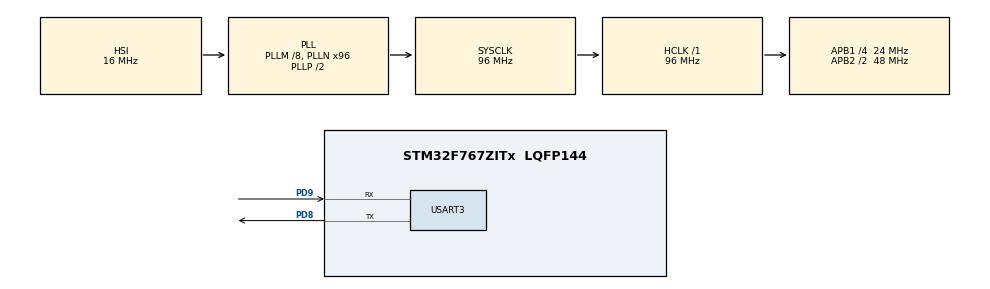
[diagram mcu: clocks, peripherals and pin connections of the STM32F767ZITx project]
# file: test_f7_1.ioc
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CORTEX_M7.CPU_DCache=Enabled
CORTEX_M7.CPU_ICache=Enabled
Mcu.Family=STM32F7
Mcu.Name=STM32F767ZITx
Mcu.Package=LQFP144
NVIC.PriorityGroup=NVIC_PRIORITYGROUP_4
PD8.Mode=Asynchronous
PD8.Signal=USART3_TX
PD9.Mode=Asynchronous
PD9.Signal=USART3_RX
PH0/OSC_IN.Mode=HSE-External-Clock-Source
PH0/OSC_IN.Signal=RCC_OSC_IN
PH1/OSC_OUT.Mode=HSE-External-Clock-Source
PH1/OSC_OUT.Signal=RCC_OSC_OUT
ProjectManager.HeapSize=0x800
ProjectManager.StackSize=0x800
ProjectManager.TargetToolchain=STM32CubeIDE
RCC.AHBFreq_Value=96000000
RCC.APB1CLKDivider=RCC_HCLK_DIV4
RCC.APB1Freq_Value=24000000
RCC.APB1TimFreq_Value=48000000
RCC.APB2CLKDivider=RCC_HCLK_DIV2
RCC.APB2Freq_Value=48000000
RCC.APB2TimFreq_Value=96000000
RCC.CortexFreq_Value=96000000
RCC.HCLKFreq_Value=96000000
RCC.HSE_VALUE=8000000
RCC.HSI_VALUE=16000000
RCC.LSE_VALUE=32768
RCC.PLLM=8
RCC.PLLMUL=RCC_PLL_MUL9
RCC.PLLN=96
RCC.PLLP=2
RCC.PLLQ=9
RCC.PRESCALERUSB=RCC_USBCLKSOURCE_PLL_DIV1_5
RCC.SYSCLKFreq_VALUE=96000000
RCC.SYSCLKSource=RCC_SYSCLKSOURCE_PLLCLK
RCC.SYSCLKSourceVirtual=RCC_SYSCLKSOURCE_PLLCLK
RCC.USBFreq_Value=21333333.333333332
RCC.VCOOutputFreq_Value=192000000
STMicroelectronics.X-CUBE-AI.7.2.0.ActivationBufferSizeList=128
STMicroelectronics.X-CUBE-AI.7.2.0.ActivationBuffers=pool0
STMicroelectronics.X-CUBE-AI.7.2.0.ActivationNames=pool0
STMicroelectronics.X-CUBE-AI.7.2.0.ActivationSizes=AI_SINE_MODEL_DATA_ACTIVATION_1_SIZE
STMicroelectronics.X-CUBE-AI.7.2.0.HeapSize=0x800
STMicroelectronics.X-CUBE-AI.7.2.0.InternalRamActivationBufferMaxSize=AI_SINE_MODEL_DATA_ACTIVATIONS_SIZE
STMicroelectronics.X-CUBE-AI.7.2.0.LatestDirectoryUsed-2042de53a2b5c42e7742469bd244823b2a5d994d889c02ff18ed5b614911f356=C\:\\Users\\iresh\\OneDrive\\Desktop\\Edge AI\\impl
STMicroelectronics.X-CUBE-AI.7.2.0.MaximumNumberOfInputLayer=1
STMicroelectronics.X-CUBE-AI.7.2.0.MaximumNumberOfOutputLayer=1
STMicroelectronics.X-CUBE-AI.7.2.0.MaximumSizeOfInputLayer=1
STMicroelectronics.X-CUBE-AI.7.2.0.MaximumSizeOfOutputLayer=1
STMicroelectronics.X-CUBE-AI.7.2.0.ModelActualCompression-2042de53a2b5c42e7742469bd244823b2a5d994d889c02ff18ed5b614911f356=0.0
STMicroelectronics.X-CUBE-AI.7.2.0.ModelCompression-2042de53a2b5c42e7742469bd244823b2a5d994d889c02ff18ed5b614911f356=Low
STMicroelectronics.X-CUBE-AI.7.2.0.ModelFlashOccupation-2042de53a2b5c42e7742469bd244823b2a5d994d889c02ff18ed5b614911f356=1284
STMicroelectronics.X-CUBE-AI.7.2.0.ModelHashList=2042de53a2b5c42e7742469bd244823b2a5d994d889c02ff18ed5b614911f356
STMicroelectronics.X-CUBE-AI.7.2.0.ModelKind-2042de53a2b5c42e7742469bd244823b2a5d994d889c02ff18ed5b614911f356=TFLITE
STMicroelectronics.X-CUBE-AI.7.2.0.ModelMacc-2042de53a2b5c42e7742469bd244823b2a5d994d889c02ff18ed5b614911f356=353
STMicroelectronics.X-CUBE-AI.7.2.0.ModelName-2042de53a2b5c42e7742469bd244823b2a5d994d889c02ff18ed5b614911f356=sine_model
STMicroelectronics.X-CUBE-AI.7.2.0.ModelNameList=sine_model
STMicroelectronics.X-CUBE-AI.7.2.0.ModelRamOccupation-2042de53a2b5c42e7742469bd244823b2a5d994d889c02ff18ed5b614911f356=128
STMicroelectronics.X-CUBE-AI.7.2.0.ModelStructureFile-2042de53a2b5c42e7742469bd244823b2a5d994d889c02ff18ed5b614911f356=C\:\\Users\\iresh\\OneDrive\\Desktop\\Edge AI\\impl\\sine_model.tflite
STMicroelectronics.X-CUBE-AI.7.2.0.ModelType-2042de53a2b5c42e7742469bd244823b2a5d994d889c02ff18ed5b614911f356=STM32Cube.AI runtime
STMicroelectronics.X-CUBE-AI.7.2.0.ReadyForCodeGeneration=true
STMicroelectronics.X-CUBE-AI.7.2.0.StackSize=0x800
STMicroelectronics.X-CUBE-AI.7.2.0.WorkingBufferStartAddrList=0xFFFFFFFF
STMicroelectronics.X-CUBE-AI.7.2.0.XAaCUBEAaAICcArtificialOoIntelligenceJjCore=true
USART3.VirtualMode-Asynchronous=VM_ASYNC
VP_CRC_VS_CRC.Mode=CRC_Activate
VP_STMicroelectronics.X-CUBE-AI_VS_ArtificialOoIntelligenceJjXAaCUBEAaAI_7.2.0.Mode=ArtificialOoIntelligenceJjXAaCUBEAaAI
board=custom

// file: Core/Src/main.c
/* USER CODE BEGIN Header */
/**
  ******************************************************************************
  * @file           : main.c
  * @brief          : Main program body
  ******************************************************************************
  * @attention
  *
  * Copyright (c) 2022 STMicroelectronics.
  * All rights reserved.
  *
  * This software is licensed under terms that can be found in the LICENSE file
  * in the root directory of this software component.
  * If no LICENSE file comes with this software, it is provided AS-IS.
  *
  ******************************************************************************
  */
/* USER CODE END Header */
#include "main.h"
#include "crc.h"
#include "usart.h"
#include "gpio.h"

/* USER CODE BEGIN Includes */
#include <stdio.h>

#include "ai_datatypes_defines.h"
#include "ai_platform.h"
#include "sine_model.h"
#include "sine_model_data.h"
/* USER CODE END Includes */

/* USER CODE BEGIN PV */
  AI_ALIGNED(4) ai_u8 in_data[AI_SINE_MODEL_IN_1_SIZE_BYTES];
  AI_ALIGNED(4) ai_u8 out_data[AI_SINE_MODEL_OUT_1_SIZE_BYTES];
  float y_val = 0;
/* USER CODE END PV */

void SystemClock_Config(void);

int main(void)
{
  /* USER CODE BEGIN 1 */

  char buf[50];
  int buf_len = 0;

//  ai_buffer ai_input[AI_SINE_MODEL_IN_NUM] = AI_SINE_MODEL_IN;
//  ai_buffer ai_output[AI_SINE_MODEL_OUT_NUM] = AI_SINE_MODEL_OUT;
//
//  ai_handle sine_model = AI_HANDLE_NULL;

  /* USER CODE END 1 */

  /* Enable I-Cache---------------------------------------------------------*/
  SCB_EnableICache();

  /* Enable D-Cache---------------------------------------------------------*/
  SCB_EnableDCache();

  /* MCU Configuration--------------------------------------------------------*/

  /* Reset of all peripherals, Initializes the Flash interface and the Systick. */
  HAL_Init();

  /* Configure the system clock */
  SystemClock_Config();

  /* Initialize all configured peripherals */
  MX_GPIO_Init();
  MX_USART3_UART_Init();
  MX_CRC_Init();
  /* USER CODE BEGIN 2 */
  buf_len = sprintf(buf, "\r\n\r\nSTM32 X-Cube-AI test\r\n");
  HAL_UART_Transmit(&huart3, (uint8_t *)buf, buf_len, 100);

  ai_u8 activations[AI_SINE_MODEL_DATA_ACTIVATIONS_SIZE];
  ai_u8 weithtsNew[AI_SINE_MODEL_DATA_WEIGHTS_SIZE];

  /* AI buffer IO handlers */
  ai_buffer *ai_input;
  ai_buffer *ai_output;
  ai_handle network = AI_HANDLE_NULL;

      ai_error err;
      ai_network_report report;

      /** @brief Initialize network */
      const ai_handle acts[] = { activations };

      err = ai_sine_model_create_and_init(&network, acts, NULL);
      if (err.type != AI_ERROR_NONE) {
		  buf_len = sprintf(buf, "Error: could not create NN instance\r\n");
		  HAL_UART_Transmit(&huart3, (uint8_t *)buf, buf_len, 100);
          //return -1;
      }
      else
      {
		  buf_len = sprintf(buf, "success in create NN instance\r\n");
		  HAL_UART_Transmit(&huart3, (uint8_t *)buf, buf_len, 100);
      }

      if (ai_sine_model_get_report(network, &report) != true) {
    	  buf_len = sprintf(buf, "ai get report error\r\n");
    	  HAL_UART_Transmit(&huart3, (uint8_t *)buf, buf_len, 100);
      }
      /*
      buf_len = sprintf(buf, "Model name      : ");
      HAL_UART_Transmit(&huart3, (uint8_t *)buf, buf_len, 100);
      buf_len = sprintf(buf, report.model_name);
      HAL_UART_Transmit(&huart3, (uint8_t *)buf, buf_len, 100);
      buf_len = sprintf(buf, "\nModel signature : ");
      HAL_UART_Transmit(&huart3, (uint8_t *)buf, buf_len, 100);
      buf_len = sprintf(buf, report.model_signature);
      HAL_UART_Transmit(&huart3, (uint8_t *)buf, buf_len, 100);
*/
      ai_input = &report.inputs[0];
      ai_output = &report.outputs[0];

//link inputs and outputs to the model
      ai_input[0].data = AI_HANDLE_PTR(in_data);
      ai_output[0].data = AI_HANDLE_PTR(out_data);

      ai_i32 nbatch;

  // Create instance of neural network
  /* USER CODE END 2 */

  /* Infinite loop */
  /* USER CODE BEGIN WHILE */
  while (1)
  {

	  float x = 0.0f;

	  for (int i = 0 ; i < 60; i++){
		  x = x + 0.1;

		  for (uint32_t i = 0; i < AI_SINE_MODEL_IN_1_SIZE; i++)
			  {
				((ai_float *)in_data)[i] = (ai_float)x;
			  }

		  nbatch = ai_sine_model_run(network, &ai_input[0], &ai_output[0]);
		  if (nbatch != 1) {
			  buf_len = sprintf(buf, "Error: could not run inference\r\n");
			  HAL_UART_Transmit(&huart3, (uint8_t *)buf, buf_len, 100);
			}

		  y_val = ((float *)out_data)[0];

		  buf_len = sprintf(buf, "%f \r\n",y_val);

		  HAL_UART_Transmit(&huart3, (uint8_t *)buf, buf_len, 100);

		  HAL_Delay (50);
}
	  while(1);
    /* USER CODE END WHILE */

  }
}

void SystemClock_Config(void)
{
  RCC_OscInitTypeDef RCC_OscInitStruct = {0};
  RCC_ClkInitTypeDef RCC_ClkInitStruct = {0};

  /** Configure the main internal regulator output voltage
  */
  __HAL_RCC_PWR_CLK_ENABLE();
  __HAL_PWR_VOLTAGESCALING_CONFIG(PWR_REGULATOR_VOLTAGE_SCALE3);

  /** Initializes the RCC Oscillators according to the specified parameters
  * in the RCC_OscInitTypeDef structure.
  */
  RCC_OscInitStruct.OscillatorType = RCC_OSCILLATORTYPE_HSI;
  RCC_OscInitStruct.HSIState = RCC_HSI_ON;
  RCC_OscInitStruct.HSICalibrationValue = RCC_HSICALIBRATION_DEFAULT;
  RCC_OscInitStruct.PLL.PLLState = RCC_PLL_ON;
  RCC_OscInitStruct.PLL.PLLSource = RCC_PLLSOURCE_HSI;
  RCC_OscInitStruct.PLL.PLLM = 8;
  RCC_OscInitStruct.PLL.PLLN = 96;
  RCC_OscInitStruct.PLL.PLLP = 2;
  RCC_OscInitStruct.PLL.PLLQ = 9;
  RCC_OscInitStruct.PLL.PLLR = 2;
  if (HAL_RCC_OscConfig(&RCC_OscInitStruct) != HAL_OK)
  {
    Error_Handler();
  }

  /** Initializes the CPU, AHB and APB buses clocks
  */
  RCC_ClkInitStruct.ClockType = RCC_CLOCKTYPE_HCLK|RCC_CLOCKTYPE_SYSCLK
                              |RCC_CLOCKTYPE_PCLK1|RCC_CLOCKTYPE_PCLK2;
  RCC_ClkInitStruct.SYSCLKSource = RCC_SYSCLKSOURCE_PLLCLK;
  RCC_ClkInitStruct.AHBCLKDivider = RCC_SYSCLK_DIV1;
  RCC_ClkInitStruct.APB1CLKDivider = RCC_HCLK_DIV4;
  RCC_ClkInitStruct.APB2CLKDivider = RCC_HCLK_DIV2;

  if (HAL_RCC_ClockConfig(&RCC_ClkInitStruct, FLASH_LATENCY_3) != HAL_OK)
  {
    Error_Handler();
  }
}

void Error_Handler(void)
{
  __disable_irq();
  while (1)
  {
  }
}
